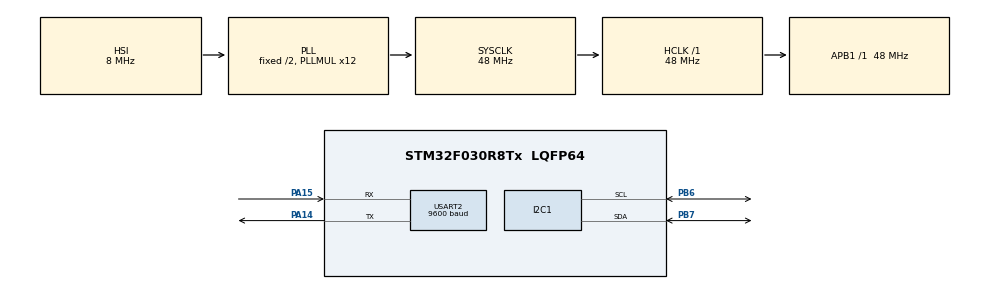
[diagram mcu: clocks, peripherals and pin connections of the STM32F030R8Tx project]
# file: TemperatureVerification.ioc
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Mcu.Family=STM32F0
Mcu.Name=STM32F030R8Tx
Mcu.Package=LQFP64
NVIC.USART2_IRQn=true\:0\:0\:false\:false\:true\:true\:true
PA13.GPIO_Label=SWDIO
PA13.Signal=SYS_SWDIO
PA14.Mode=Asynchronous
PA14.Signal=USART2_TX
PA15.Mode=Asynchronous
PA15.Signal=USART2_RX
PB6.Mode=I2C
PB6.Signal=I2C1_SCL
PB7.Mode=I2C
PB7.Signal=I2C1_SDA
ProjectManager.HeapSize=0x200
ProjectManager.StackSize=0x400
ProjectManager.TargetToolchain=STM32CubeIDE
RCC.AHBFreq_Value=48000000
RCC.APB1Freq_Value=48000000
RCC.APB1TimFreq_Value=48000000
RCC.HCLKFreq_Value=48000000
RCC.PLLMUL=RCC_PLL_MUL12
RCC.SYSCLKFreq_VALUE=48000000
RCC.SYSCLKSource=RCC_SYSCLKSOURCE_PLLCLK
USART2.BaudRate=9600
USART2.VirtualMode-Asynchronous=VM_ASYNC
board=STM32F0308-DISCO

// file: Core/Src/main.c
/* USER CODE BEGIN Header */
/**
  ******************************************************************************
  * @file           : main.c
  * @brief          : Main program body
  ******************************************************************************
  * @attention
  *
  * <h2><center>&copy; Copyright (c) 2020 STMicroelectronics.
  * All rights reserved.</center></h2>
  *
  * This software component is licensed by ST under BSD 3-Clause license,
  * the "License"; You may not use this file except in compliance with the
  * License. You may obtain a copy of the License at:
  *                        opensource.org/licenses/BSD-3-Clause
  *
  ******************************************************************************
  jeszcze raz otwórz mi plik z biblioteką
  #include "Adafruit_MLX90614.h"
jaki WProgram.h xd wlasnie widze co tu sie...
  */
/* USER CODE END Header */

#include "main.h"

/* USER CODE BEGIN Includes */
 static const uint8_t TMP102_ADDR = 0x48 << 1; // Use 8-bit address
static const uint8_t REG_TEMP = 0x00;
HAL_StatusTypeDef ret;
  uint8_t buf[12];
  int16_t val;
  float temp_c;
/* USER CODE END Includes */

I2C_HandleTypeDef hi2c1;

UART_HandleTypeDef huart2;

void SystemClock_Config(void);
static void MX_GPIO_Init(void);
static void MX_USART2_UART_Init(void);
static void MX_I2C1_Init(void);
/* USER CODE BEGIN PFP */
static uint16_t cnt = 0;
uint8_t data[50];
uint16_t size = 0;
//size = sprintf(data, "miaona %d \n\r",cnt);
/* USER CODE END PFP */

int main(void)
{

  /* MCU Configuration--------------------------------------------------------*/

  /* Reset of all peripherals, Initializes the Flash interface and the Systick. */
  HAL_Init();

  /* Configure the system clock */
  SystemClock_Config();

  /* Initialize all configured peripherals */
  MX_GPIO_Init();
  MX_USART2_UART_Init();
  MX_I2C1_Init();

  /* Infinite loop */
  while (1)
  {
	  buf[0] = REG_TEMP;
	  ret = HAL_I2C_Master_Transmit(&hi2c1, TMP102_ADDR, buf, 1, HAL_MAX_DELAY);
	    if ( ret != HAL_OK ) {
	      strcpy((char*)buf, "Error Tx\r\n");
	    } else {

	      // Read 2 bytes from the temperature register
	      ret = HAL_I2C_Master_Receive(&hi2c1, TMP102_ADDR, buf, 2, HAL_MAX_DELAY);
	      if ( ret != HAL_OK ) {
	        strcpy((char*)buf, "Error Rx\r\n");
	      } else {

	        //Combine the bytes
	        val = ((int16_t)buf[0] << 4) | (buf[1] >> 4);

	        // Convert to 2's complement, since temperature can be negative
	        if ( val > 0x7FF ) {
	          val |= 0xF000;
	        }

	        // Convert to float temperature value (Celsius)
	        temp_c = val * 0.0625;

	        // Convert temperature to decimal format
	        temp_c *= 100;
	        sprintf((char*)buf,
	              "%u.%u C\r\n",
	              ((unsigned int)temp_c / 100),
	              ((unsigned int)temp_c % 100));
	      }
	    }

	    // Send out buffer (temperature or error message)
	    HAL_UART_Transmit(&huart2, buf, strlen((char*)buf), HAL_MAX_DELAY);

	    // Wait
	    HAL_Delay(500);
  }
}

void SystemClock_Config(void)
{
  RCC_OscInitTypeDef RCC_OscInitStruct = {0};
  RCC_ClkInitTypeDef RCC_ClkInitStruct = {0};
  RCC_PeriphCLKInitTypeDef PeriphClkInit = {0};

  /** Initializes the CPU, AHB and APB busses clocks
  */
  RCC_OscInitStruct.OscillatorType = RCC_OSCILLATORTYPE_HSI;
  RCC_OscInitStruct.HSIState = RCC_HSI_ON;
  RCC_OscInitStruct.HSICalibrationValue = RCC_HSICALIBRATION_DEFAULT;
  RCC_OscInitStruct.PLL.PLLState = RCC_PLL_ON;
  RCC_OscInitStruct.PLL.PLLSource = RCC_PLLSOURCE_HSI;
  RCC_OscInitStruct.PLL.PLLMUL = RCC_PLL_MUL12;
  RCC_OscInitStruct.PLL.PREDIV = RCC_PREDIV_DIV1;
  if (HAL_RCC_OscConfig(&RCC_OscInitStruct) != HAL_OK)
  {
    Error_Handler();
  }
  /** Initializes the CPU, AHB and APB busses clocks
  */
  RCC_ClkInitStruct.ClockType = RCC_CLOCKTYPE_HCLK|RCC_CLOCKTYPE_SYSCLK
                              |RCC_CLOCKTYPE_PCLK1;
  RCC_ClkInitStruct.SYSCLKSource = RCC_SYSCLKSOURCE_PLLCLK;
  RCC_ClkInitStruct.AHBCLKDivider = RCC_SYSCLK_DIV1;
  RCC_ClkInitStruct.APB1CLKDivider = RCC_HCLK_DIV1;

  if (HAL_RCC_ClockConfig(&RCC_ClkInitStruct, FLASH_LATENCY_1) != HAL_OK)
  {
    Error_Handler();
  }
  PeriphClkInit.PeriphClockSelection = RCC_PERIPHCLK_I2C1;
  PeriphClkInit.I2c1ClockSelection = RCC_I2C1CLKSOURCE_HSI;
  if (HAL_RCCEx_PeriphCLKConfig(&PeriphClkInit) != HAL_OK)
  {
    Error_Handler();
  }
}

static void MX_I2C1_Init(void)
{

  hi2c1.Instance = I2C1;
  hi2c1.Init.Timing = 0x2000090E;
  hi2c1.Init.OwnAddress1 = 0;
  hi2c1.Init.AddressingMode = I2C_ADDRESSINGMODE_7BIT;
  hi2c1.Init.DualAddressMode = I2C_DUALADDRESS_DISABLE;
  hi2c1.Init.OwnAddress2 = 0;
  hi2c1.Init.OwnAddress2Masks = I2C_OA2_NOMASK;
  hi2c1.Init.GeneralCallMode = I2C_GENERALCALL_DISABLE;
  hi2c1.Init.NoStretchMode = I2C_NOSTRETCH_DISABLE;
  if (HAL_I2C_Init(&hi2c1) != HAL_OK)
  {
    Error_Handler();
  }
  /** Configure Analogue filter
  */
  if (HAL_I2CEx_ConfigAnalogFilter(&hi2c1, I2C_ANALOGFILTER_ENABLE) != HAL_OK)
  {
    Error_Handler();
  }
  /** Configure Digital filter
  */
  if (HAL_I2CEx_ConfigDigitalFilter(&hi2c1, 0) != HAL_OK)
  {
    Error_Handler();
  }

}

static void MX_USART2_UART_Init(void)
{

  huart2.Instance = USART2;
  huart2.Init.BaudRate = 9600;
  huart2.Init.WordLength = UART_WORDLENGTH_8B;
  huart2.Init.StopBits = UART_STOPBITS_1;
  huart2.Init.Parity = UART_PARITY_NONE;
  huart2.Init.Mode = UART_MODE_TX_RX;
  huart2.Init.HwFlowCtl = UART_HWCONTROL_NONE;
  huart2.Init.OverSampling = UART_OVERSAMPLING_16;
  huart2.Init.OneBitSampling = UART_ONE_BIT_SAMPLE_DISABLE;
  huart2.AdvancedInit.AdvFeatureInit = UART_ADVFEATURE_NO_INIT;
  if (HAL_UART_Init(&huart2) != HAL_OK)
  {
    Error_Handler();
  }

}

static void MX_GPIO_Init(void)
{

  /* GPIO Ports Clock Enable */
  __HAL_RCC_GPIOA_CLK_ENABLE();
  __HAL_RCC_GPIOB_CLK_ENABLE();

}

void Error_Handler(void)
{
}

/************************ (C) COPYRIGHT STMicroelectronics *****END OF FILE****/
